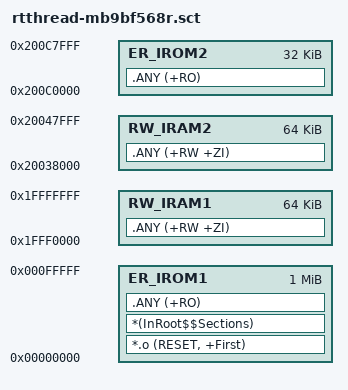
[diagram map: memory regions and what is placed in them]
; *************************************************************
; *** Scatter-Loading Description File generated by uVision ***
; *************************************************************

LR_IROM1 0x00000000 0x00100000  {    ; load region size_region
  ER_IROM1 0x00000000 0x00100000  {  ; load address = execution address
   *.o (RESET, +First)
   *(InRoot$$Sections)
   .ANY (+RO)
  }
  RW_IRAM1 0x1FFF0000 0x00010000  {  ; RW data
   .ANY (+RW +ZI)
  }
  RW_IRAM2 0x20038000 0x00010000  {
   .ANY (+RW +ZI)
  }
}

LR_IROM2 0x200C0000 0x00008000  {
  ER_IROM2 0x200C0000 0x00008000  {  ; load address = execution address
   .ANY (+RO)
  }
}
